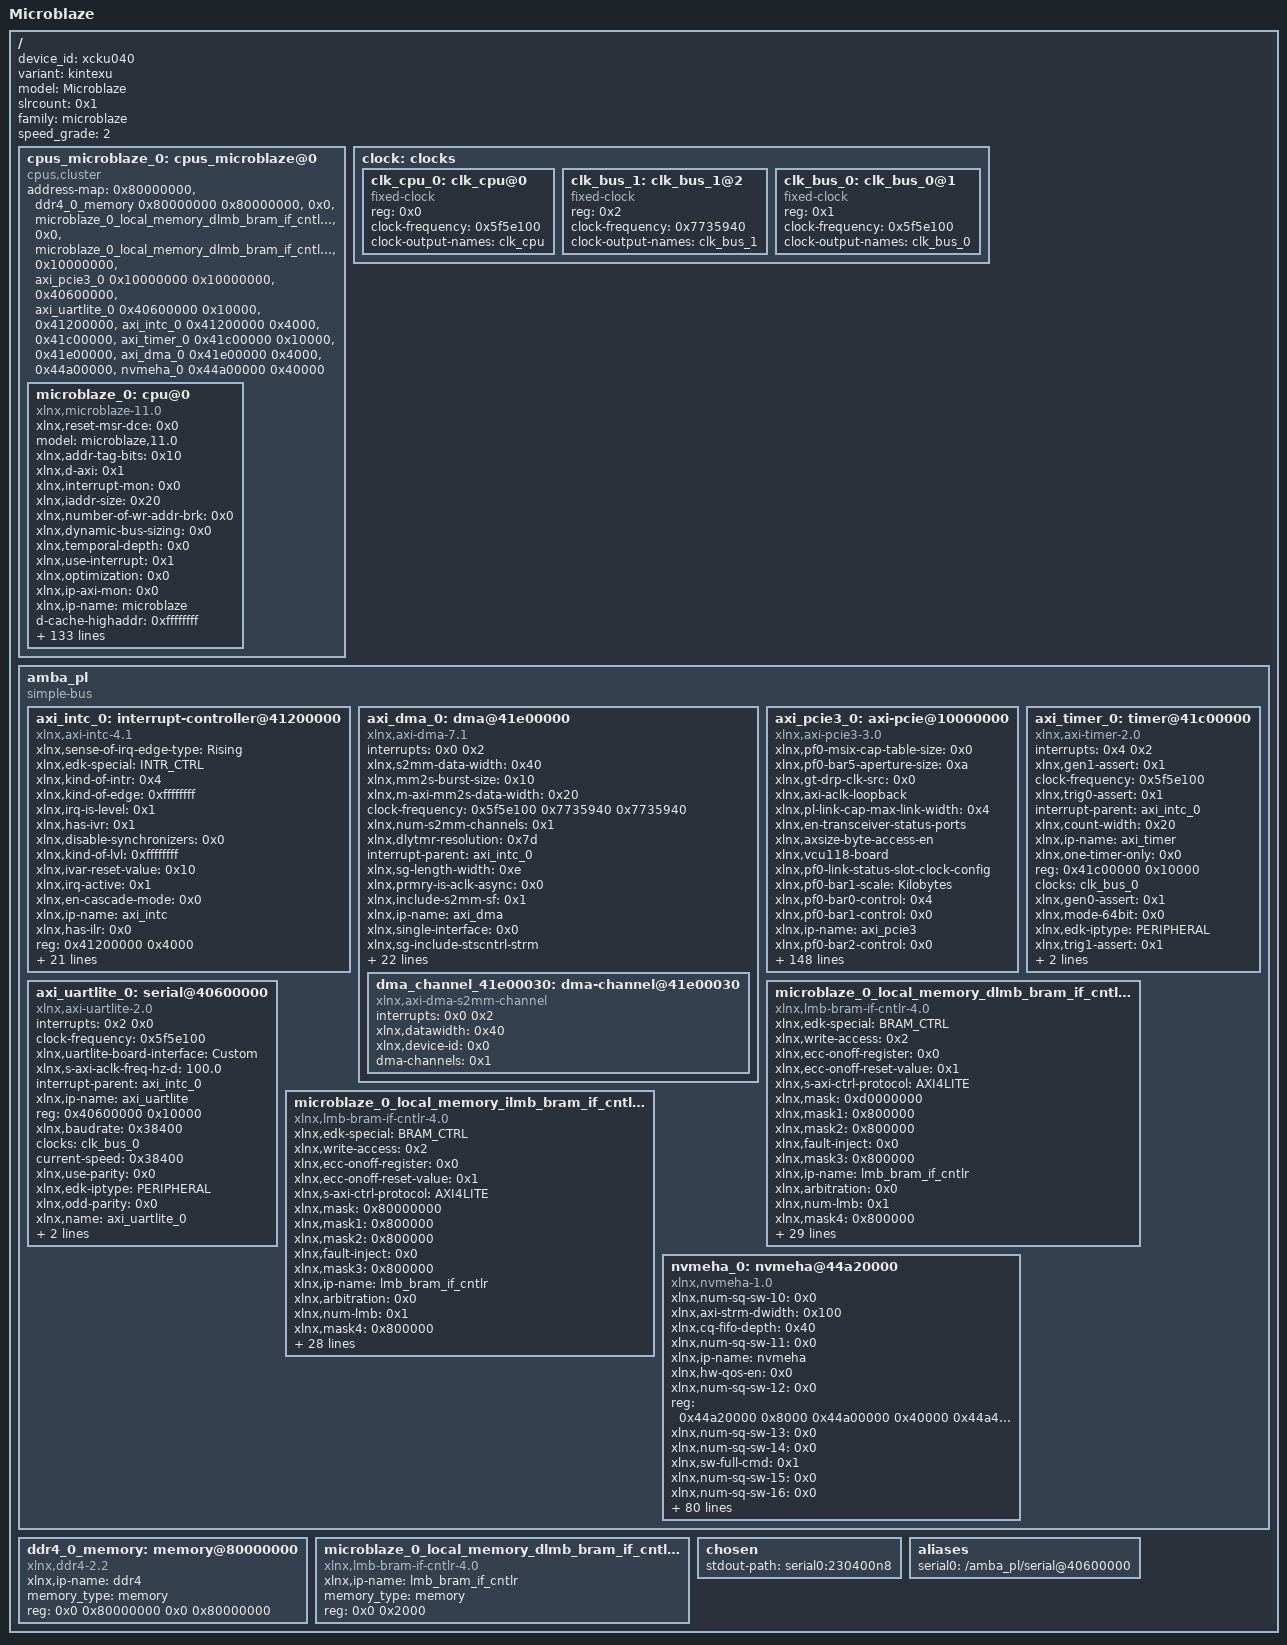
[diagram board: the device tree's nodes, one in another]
/dts-v1/;
/ {
        device_id = "xcku040";
        #address-cells = <0x1>;
        variant = "kintexu";
        model = "Microblaze";
        #size-cells = <0x1>;
        slrcount = <0x1>;
        family = "microblaze";
        speed_grade = "2";

        cpus_microblaze_0: cpus_microblaze@0 {
                phandle = <0xd>;
                #cpu-mask-cells = <0x1>;
                compatible = "cpus,cluster";
                #address-cells = <0x1>;
                #size-cells = <0x0>;
                address-map = <0x80000000 &ddr4_0_memory 0x80000000 0x80000000>,
                 <0x0 &microblaze_0_local_memory_dlmb_bram_if_cntlr_memory 0x0 0x2000>,
                 <0x0 &microblaze_0_local_memory_dlmb_bram_if_cntlr 0x0 0x2000>,
                 <0x10000000 &axi_pcie3_0 0x10000000 0x10000000>,
                 <0x40600000 &axi_uartlite_0 0x40600000 0x10000>,
                 <0x41200000 &axi_intc_0 0x41200000 0x4000>,
                 <0x41c00000 &axi_timer_0 0x41c00000 0x10000>,
                 <0x41e00000 &axi_dma_0 0x41e00000 0x4000>,
                 <0x44a00000 &nvmeha_0 0x44a00000 0x40000>;
                #ranges-address-cells = <0x1>;
                #ranges-size-cells = <0x1>;

                microblaze_0: cpu@0 {
                        phandle = <0xe>;
                        xlnx,reset-msr-dce = <0x0>;
                        model = "microblaze,11.0";
                        xlnx,addr-tag-bits = <0x10>;
                        xlnx,d-axi = <0x1>;
                        xlnx,interrupt-mon = <0x0>;
                        xlnx,iaddr-size = <0x20>;
                        xlnx,number-of-wr-addr-brk = <0x0>;
                        xlnx,dynamic-bus-sizing = <0x0>;
                        xlnx,temporal-depth = <0x0>;
                        xlnx,use-interrupt = <0x1>;
                        xlnx,optimization = <0x0>;
                        xlnx,ip-axi-mon = <0x0>;
                        xlnx,ip-name = "microblaze";
                        d-cache-highaddr = <0xffffffff>;
                        xlnx,dcache-force-tag-lutram = <0x0>;
                        xlnx,pc-width = <0x20>;
                        xlnx,interrupt-is-edge = <0x0>;
                        reg = <0x0>;
                        xlnx,async-interrupt = <0x1>;
                        xlnx,use-mmu = <0x3>;
                        xlnx,reset-msr-ee = <0x0>;
                        xlnx,icache-victims = <0x8>;
                        xlnx,use-reorder-instr = <0x1>;
                        xlnx,d-lmb-mon = <0x0>;
                        xlnx,d-lmb-protocol = <0x0>;
                        xlnx,ill-opcode-exception = <0x1>;
                        xlnx,dcache-always-used = <0x0>;
                        xlnx,use-div = <0x1>;
                        xlnx,dc-axi-mon = <0x0>;
                        xlnx,debug-trace-async-reset = <0x0>;
                        xlnx,trace = <0x0>;
                        xlnx,part = "xcku040-ffva1156-2-i";
                        i-cache-baseaddr = <0x80000000>;
                        xlnx,use-config-reset = <0x0>;
                        xlnx,pvr = <0x2>;
                        xlnx,i-lmb-mon = <0x0>;
                        xlnx,dcache-byte-size = <0x8000>;
                        xlnx,fault-tolerant = <0x0>;
                        xlnx,family = "kintexu";
                        compatible = "xlnx,microblaze-11.0", "xlnx,microblaze";
                        xlnx,data-size = <0x20>;
                        xlnx,mmu-zones = <0x2>;
                        xlnx,debug-trace-size = <0x2000>;
                        xlnx,mmu-privileged-instr = <0x0>;
                        xlnx,enable-discrete-ports = <0x0>;
                        d-cache-line-size = <0x10>;
                        xlnx,d-lmb = <0x1>;
                        xlnx,sco = <0x0>;
                        xlnx,reset-msr-eip = <0x0>;
                        xlnx,debug-interface = <0x0>;
                        clock-frequency = <0x5f5e100>;
                        xlnx,use-ext-brk = <0x0>;
                        xlnx,daddr-size = <0x20>;
                        xlnx,debug-enabled = <0x1>;
                        xlnx,reset-msr-ice = <0x0>;
                        xlnx,num-sync-ff-dbg-trace-clk = <0x2>;
                        xlnx,i-lmb-protocol = <0x0>;
                        xlnx,endianness = <0x1>;
                        xlnx,fsl-exception = <0x0>;
                        i-cache-line-size = <0x20>;
                        xlnx,use-extended-fsl-instr = <0x0>;
                        xlnx,reset-msr = <0x0>;
                        xlnx,dp-axi-mon = <0x0>;
                        device_type = "cpu";
                        xlnx,branch-target-cache-size = <0x0>;
                        xlnx,dcache-use-writeback = <0x0>;
                        xlnx,div-zero-exception = <0x1>;
                        xlnx,mmu-tlb-access = <0x3>;
                        bus-handle = <&amba_pl>;
                        xlnx,cache-byte-size = <0x8000>;
                        xlnx,pvr-user2 = <0x0>;
                        xlnx,opcode-0x0-illegal = <0x1>;
                        xlnx,icache-line-len = <0x8>;
                        xlnx,ecc-use-ce-exception = <0x0>;
                        xlnx,base-vectors = <0x0>;
                        xlnx,d-lmb-has-prot = <0x0>;
                        xlnx,edk-special = "microblaze";
                        xlnx,use-dcache = <0x1>;
                        xlnx,use-barrel = <0x1>;
                        xlnx,reset-msr-bip = <0x0>;
                        xlnx,allow-dcache-wr = <0x1>;
                        xlnx,debug-external-trace = <0x0>;
                        xlnx,addr-size = <0x20>;
                        xlnx,piaddr-size = <0x20>;
                        i-cache-highaddr = <0xffffffff>;
                        xlnx,num-sync-ff-clk-debug = <0x2>;
                        xlnx,debug-event-counters = <0x5>;
                        xlnx,fpu-exception = <0x0>;
                        xlnx,allow-icache-wr = <0x1>;
                        xlnx,g-use-exceptions = <0x1>;
                        xlnx,i-axi = <0x0>;
                        xlnx,g-template-list = <0x4>;
                        xlnx,icache-streams = <0x1>;
                        xlnx,dcache-line-len = <0x4>;
                        xlnx,num-sync-ff-clk = <0x2>;
                        xlnx,edk-iptype = "PROCESSOR";
                        xlnx,use-stack-protection = <0x0>;
                        xlnx,use-hw-mul = <0x2>;
                        xlnx,num-sync-ff-dbg-clk = <0x1>;
                        xlnx,interconnect = <0x2>;
                        xlnx,i-lmb-has-prot = <0x0>;
                        xlnx,debug-latency-counters = <0x1>;
                        i-cache-size = <0x8000>;
                        xlnx,exceptions-in-delay-slots = <0x1>;
                        xlnx,use-fpu = <0x0>;
                        xlnx,reset-msr-ie = <0x0>;
                        xlnx,edge-is-positive = <0x1>;
                        xlnx,use-pcmp-instr = <0x1>;
                        xlnx,use-icache = <0x1>;
                        d-cache-size = <0x8000>;
                        xlnx,memory-ip-list = "microblaze_0_local_memory_ilmb_bram_if_cntlr_memory", "microblaze_0_local_memory_dlmb_bram_if_cntlr_memory", "ddr4_0_memory", "ddr4_0_memory";
                        xlnx,async-wakeup = <0x3>;
                        xlnx,use-non-secure = <0x0>;
                        xlnx,dcache-addr-tag = <0x10>;
                        xlnx,number-of-rd-addr-brk = <0x0>;
                        d-cache-baseaddr = <0x80000000>;
                        xlnx,area-optimized = <0x0>;
                        xlnx,avoid-primitives = <0x0>;
                        xlnx,lockstep-slave = <0x0>;
                        xlnx,use-ext-nm-brk = <0x0>;
                        xlnx,instr-size = <0x20>;
                        interrupt-handle = <&axi_intc_0>;
                        xlnx,icache-always-used = <0x1>;
                        xlnx,i-lmb = <0x1>;
                        xlnx,mmu-dtlb-size = <0x4>;
                        xlnx,lockstep-select = <0x0>;
                        xlnx,lmb-data-size = <0x20>;
                        xlnx,ic-axi-mon = <0x0>;
                        xlnx,enable-conversion = <0x0>;
                        xlnx,num-sync-ff-clk-irq = <0x1>;
                        xlnx,fsl-links = <0x0>;
                        timebase-frequency = <0x5f5e100>;
                        xlnx,icache-force-tag-lutram = <0x0>;
                        xlnx,dcache-data-width = <0x0>;
                        xlnx,dcache-victims = <0x8>;
                        xlnx,use-branch-target-cache = <0x0>;
                        xlnx,debug-profile-size = <0x0>;
                        xlnx,unaligned-exceptions = <0x1>;
                        xlnx,lockstep-master = <0x0>;
                        xlnx,freq = <0x5f5e100>;
                        xlnx,number-of-pc-brk = <0x1>;
                        xlnx,mmu-itlb-size = <0x2>;
                        xlnx,imprecise-exceptions = <0x0>;
                        xlnx,use-msr-instr = <0x1>;
                        xlnx,icache-data-width = <0x0>;
                        xlnx,debug-counter-width = <0x20>;
                };
        };

        clock: clocks {
                phandle = <0xf>;
                #address-cells = <0x1>;
                #size-cells = <0x0>;

                clk_cpu_0: clk_cpu@0 {
                        phandle = <0x10>;
                        compatible = "fixed-clock";
                        reg = <0x0>;
                        clock-frequency = <0x5f5e100>;
                        clock-output-names = "clk_cpu";
                        #clock-cells = <0x0>;
                };

                clk_bus_1: clk_bus_1@2 {
                        phandle = <0xc>;
                        compatible = "fixed-clock";
                        reg = <0x2>;
                        clock-frequency = <0x7735940>;
                        clock-output-names = "clk_bus_1";
                        #clock-cells = <0x0>;
                };

                clk_bus_0: clk_bus_0@1 {
                        phandle = <0xb>;
                        compatible = "fixed-clock";
                        reg = <0x1>;
                        clock-frequency = <0x5f5e100>;
                        clock-output-names = "clk_bus_0";
                        #clock-cells = <0x0>;
                };
        };

        amba_pl: amba_pl {
                phandle = <0xa>;
                ranges;
                compatible = "simple-bus";
                #address-cells = <0x1>;
                #size-cells = <0x1>;

                axi_intc_0: interrupt-controller@41200000 {
                        phandle = <0x6>;
                        #interrupt-cells = <0x2>;
                        xlnx,sense-of-irq-edge-type = "Rising";
                        xlnx,edk-special = "INTR_CTRL";
                        xlnx,kind-of-intr = <0x4>;
                        xlnx,kind-of-edge = <0xffffffff>;
                        xlnx,irq-is-level = <0x1>;
                        xlnx,has-ivr = <0x1>;
                        compatible = "xlnx,axi-intc-4.1", "xlnx,xps-intc-1.00.a";
                        xlnx,disable-synchronizers = <0x0>;
                        xlnx,kind-of-lvl = <0xffffffff>;
                        xlnx,ivar-reset-value = <0x10>;
                        xlnx,irq-active = <0x1>;
                        xlnx,en-cascade-mode = <0x0>;
                        xlnx,ip-name = "axi_intc";
                        xlnx,has-ilr = <0x0>;
                        reg = <0x41200000 0x4000>;
                        xlnx,addr-width = <0x20>;
                        xlnx,s-axi-aclk-freq-mhz = "100.0";
                        xlnx,num-sw-intr = <0x0>;
                        xlnx,irq-connection = <0x0>;
                        xlnx,num-intr-inputs = <0x5>;
                        xlnx,has-sie = <0x1>;
                        xlnx,enable-async = <0x0>;
                        xlnx,has-cie = <0x1>;
                        xlnx,num-sync-ff = <0x2>;
                        xlnx,edk-iptype = "PERIPHERAL";
                        xlnx,mb-clk-not-connected = <0x1>;
                        xlnx,has-ipr = <0x1>;
                        xlnx,sense-of-irq-level-type = "Active_High";
                        xlnx,cascade-master = <0x0>;
                        xlnx,processor-clk-freq-mhz = "100.0";
                        status = "okay";
                        xlnx,is-fast = <0x0>;
                        xlnx,has-fast = <0x0>;
                        xlnx,ivar-rst-val = <0x10>;
                        interrupt-controller;
                        xlnx,async-intr = <0xffffffeb>;
                        xlnx,name = "axi_intc_0";
                };

                axi_dma_0: dma@41e00000 {
                        phandle = <0x8>;
                        interrupts = <0x0 0x2>;
                        compatible = "xlnx,axi-dma-7.1", "xlnx,axi-dma-1.00.a";
                        xlnx,s2mm-data-width = <0x40>;
                        xlnx,mm2s-burst-size = <0x10>;
                        xlnx,m-axi-mm2s-data-width = <0x20>;
                        clock-frequency = <0x5f5e100 0x7735940 0x7735940>;
                        xlnx,num-s2mm-channels = <0x1>;
                        xlnx,dlytmr-resolution = <0x7d>;
                        interrupt-parent = <&axi_intc_0>;
                        xlnx,sg-length-width = <0xe>;
                        xlnx,prmry-is-aclk-async = <0x0>;
                        xlnx,include-s2mm-sf = <0x1>;
                        #dma-cells = <0x1>;
                        xlnx,ip-name = "axi_dma";
                        xlnx,single-interface = <0x0>;
                        xlnx,sg-include-stscntrl-strm;
                        xlnx,include-s2mm-dre = <0x0>;
                        reg = <0x41e00000 0x4000>;
                        xlnx,addr-width = <0x20>;
                        xlnx,include-s2mm = <0x1>;
                        clocks = <&clk_bus_0>,
                         <&clk_bus_1>,
                         <&clk_bus_1>;
                        xlnx,s-axis-s2mm-tdata-width = <0x40>;
                        xlnx,micro-dma = <0x0>;
                        xlnx,increase-throughput = <0x0>;
                        xlnx,mm2s-data-width = <0x20>;
                        xlnx,addrwidth = <0x20>;
                        xlnx,include-sg;
                        xlnx,sg-use-stsapp-length = <0x0>;
                        xlnx,m-axis-mm2s-tdata-width = <0x20>;
                        xlnx,edk-iptype = "PERIPHERAL";
                        xlnx,s2mm-burst-size = <0x100>;
                        xlnx,m-axi-s2mm-data-width = <0x40>;
                        xlnx,num-mm2s-channels = <0x1>;
                        xlnx,enable-multi-channel = <0x0>;
                        status = "okay";
                        xlnx,include-mm2s-sf = <0x1>;
                        clock-names = "s_axi_lite_aclk", "m_axi_sg_aclk", "m_axi_s2mm_aclk";
                        interrupt-names = "s2mm_introut";
                        xlnx,include-mm2s = <0x0>;
                        xlnx,include-mm2s-dre = <0x0>;
                        xlnx,name = "axi_dma_0";

                        dma_channel_41e00030: dma-channel@41e00030 {
                                phandle = <0x11>;
                                interrupts = <0x0 0x2>;
                                xlnx,datawidth = <0x40>;
                                xlnx,device-id = <0x0>;
                                compatible = "xlnx,axi-dma-s2mm-channel";
                                dma-channels = <0x1>;
                        };
                };

                axi_pcie3_0: axi-pcie@10000000 {
                        phandle = <0x4>;
                        xlnx,pf0-msix-cap-table-size = <0x0>;
                        xlnx,pf0-bar5-aperture-size = <0xa>;
                        xlnx,gt-drp-clk-src = <0x0>;
                        xlnx,axi-aclk-loopback;
                        xlnx,pl-link-cap-max-link-width = <0x4>;
                        xlnx,en-transceiver-status-ports;
                        xlnx,axsize-byte-access-en;
                        xlnx,vcu118-board;
                        xlnx,pf0-link-status-slot-clock-config;
                        xlnx,pf0-bar1-scale = "Kilobytes";
                        xlnx,pf0-bar0-control = <0x4>;
                        xlnx,pf0-bar1-control = <0x0>;
                        xlnx,ip-name = "axi_pcie3";
                        xlnx,pf0-bar2-control = <0x0>;
                        xlnx,pf0-bar0-enabled;
                        reg = <0x10000000 0x10000000 0x76000000 0x100000 0x76100000 0x100000 0x10000000 0x4000>;
                        xlnx,user-clk-freq = <0x2>;
                        xlnx,pf0-class-code = <0x60700>;
                        xlnx,pf0-bar3-control = <0x0>;
                        xlnx,msix-en;
                        xlnx,pf0-bar5-scale = "Kilobytes";
                        xlnx,pf0-bar4-control = <0x0>;
                        xlnx,pf0-bar3-type = "Memory";
                        xlnx,enable-ibert;
                        xlnx,silicon-rev = "Production";
                        xlnx,pf0-bar5-control = <0x0>;
                        xlnx,pf0-revision-id = <0x0>;
                        xlnx,pf0-interrupt-pin = <0x1>;
                        xlnx,axibar-0 = <0x76000000>;
                        xlnx,pf0-device-id = <0x8134>;
                        xlnx,pf0-bar5-size = <0x4>;
                        xlnx,pf0-bar0-aperture-size = <0xa>;
                        xlnx,gt-tx-pd;
                        xlnx,pr-cap-nextptr = <0x0>;
                        xlnx,axibar-1 = <0x30000000>;
                        xlnx,en-axi-slave-if;
                        xlnx,axi-data-width = <0x100>;
                        xlnx,axibar-2 = <0x0>;
                        xlnx,type1-prefetchable-membase-memlimit = "Disabled";
                        xlnx,pf0-class-code-interface = <0x0>;
                        xlnx,pf0-bar0-type = "Memory";
                        xlnx,mcap-fpga-bitstream-version = <0x0>;
                        xlnx,axibar-3 = <0x0>;
                        interrupt-names = "interrupt_out";
                        xlnx,select-quad = "GTH_Quad_227";
                        xlnx,axibar-4 = <0x0>;
                        xlnx,include-baroffset-reg = <0x1>;
                        xlnx,pf0-bar4-aperture-size = <0xa>;
                        xlnx,s-axi-id-width = <0x4>;
                        xlnx,axibar-5 = <0x0>;
                        xlnx,pf0-bar2-size = <0x4>;
                        xlnx,enable-auto-rxeq;
                        compatible = "xlnx,axi-pcie3-3.0";
                        xlnx,cfg-ext-if;
                        xlnx,sys-rst-n-board-interface = "Custom";
                        xlnx,pciebar-num = <0x1>;
                        xlnx,ats-cap-nextptr = <0x0>;
                        xlnx,pf0-subsystem-id = <0x7>;
                        xlnx,axibar-num = <0x2>;
                        xlnx,pf0-bar0-scale = "Kilobytes";
                        xlnx,pciebar2axibar-1-sec = <0x0>;
                        interrupt-parent = <&axi_intc_0>;
                        xlnx,phy-lp-txpreset = <0x4>;
                        xlnx,coreclk-freq = <0xfa>;
                        xlnx,en-axi-master-if;
                        xlnx,pciebar2axibar-3-sec = <0x0>;
                        xlnx,rx-ppm-offset = <0x0>;
                        xlnx,pf0-sub-class-interface-menu = "CardBus_bridge";
                        xlnx,mode-selection = "Advanced";
                        xlnx,vu9p-board;
                        xlnx,ultrascale-plus;
                        xlnx,pf0-bar4-scale = "Kilobytes";
                        xlnx,pciebar2axibar-5-sec = <0x0>;
                        xlnx,m-axi-num-write = <0x8>;
                        xlnx,pf0-vendor-id = <0x10ee>;
                        xlnx,last-core-cap-addr = <0x100>;
                        xlnx,pipe-sim;
                        xlnx,pf0-msix-impl-locn = "External";
                        xlnx,pf0-msix-cap-table-bir = "BAR_0";
                        xlnx,pf0-bar5-type = "Memory";
                        xlnx,axibar-highaddr-0 = <0x760fffff>;
                        xlnx,axibar-highaddr-1 = <0x3fffffff>;
                        status = "okay";
                        xlnx,axibar-highaddr-2 = <0x0>;
                        xlnx,pll-type = <0x2>;
                        xlnx,pf0-subsystem-vendor-id = <0x10ee>;
                        xlnx,pf0-msix-cap-pba-bir = "BAR_0";
                        xlnx,axibar-highaddr-3 = <0x0>;
                        xlnx,pf0-msi-cap-multimsgcap = <0x0>;
                        xlnx,pf0-bar3-aperture-size = <0xa>;
                        xlnx,dev-port-type = <0x2>;
                        xlnx,timeout0-sel = <0xe>;
                        xlnx,axibar-highaddr-4 = <0x0>;
                        xlnx,pf0-class-code-base = <0x6>;
                        xlnx,pf0-bar2-type = "Memory";
                        xlnx,msi-enabled;
                        xlnx,name = "axi_pcie3_0";
                        xlnx,axibar-highaddr-5 = <0x0>;
                        interrupts = <0x3 0x2>;
                        xlnx,plltype = "QPLL1";
                        xlnx,vsec-cap-addr = <0x128>;
                        xlnx,pf0-base-class-menu = "Bridge_device";
                        xlnx,pf0-bar4-size = <0x4>;
                        xlnx,is-board-project = <0x0>;
                        xlnx,timeout-mult = <0x3>;
                        xlnx,axi-addr-width = <0x20>;
                        xlnx,axisten-freq = <0x7d>;
                        xlnx,pf0-bar3-scale = "Kilobytes";
                        xlnx,s-axi-num-read = <0x8>;
                        xlnx,pf0-bar1-size = <0x4>;
                        xlnx,comp-timeout = <0x0>;
                        xlnx,edk-iptype = "PERIPHERAL";
                        xlnx,ins-loss-nyq = <0xf>;
                        xlnx,msix-impl-ext;
                        xlnx,ins-loss-profile = "Add-in_Card";
                        xlnx,pf0-bar2-aperture-size = <0xa>;
                        xlnx,vendor-id = "10EE";
                        xlnx,ultrascale;
                        xlnx,sys-reset-polarity = <0x0>;
                        xlnx,rx-detect = <0x0>;
                        xlnx,pf0-class-code-sub = <0x7>;
                        xlnx,m-axi-num-read = <0x8>;
                        xlnx,pf0-bar4-type = "Memory";
                        xlnx,pl-link-cap-max-link-speed = <0x4>;
                        xlnx,enable-jtag-dbg;
                        xlnx,pciebar2axibar-0-sec = <0x0>;
                        xlnx,pf0-msix-cap-table-offset = <0x0>;
                        xlnx,pciebar2axibar-2-sec = <0x0>;
                        xlnx,pf0-bar2-scale = "Kilobytes";
                        xlnx,pf0-bar1-type = "Memory";
                        xlnx,pcie-blk-locn = <0x1>;
                        xlnx,pciebar2axibar-4-sec = <0x0>;
                        xlnx,shared-logic = <0x1>;
                        xlnx,rx-ssc-ppm = <0x0>;
                        xlnx,pf0-bar3-size = <0x4>;
                        xlnx,core-clk-freq = <0x1>;
                        xlnx,pf0-msi-enabled;
                        xlnx,pcie-board-interface = "Custom";
                        xlnx,axibar2pciebar-0 = <0x0>;
                        xlnx,pciebar2axibar-0 = <0x0>;
                        xlnx,no-slv-err;
                        xlnx,axibar2pciebar-1 = <0x0>;
                        xlnx,old-bridge-timeout = <0x0>;
                        xlnx,pciebar2axibar-1 = <0x0>;
                        xlnx,pf0-bar1-aperture-size = <0xa>;
                        xlnx,axibar2pciebar-2 = <0x0>;
                        xlnx,pciebar2axibar-2 = <0x0>;
                        xlnx,ref-clk-freq = <0x0>;
                        xlnx,s-axi-num-write = <0x8>;
                        xlnx,axibar2pciebar-3 = <0x0>;
                        xlnx,pciebar2axibar-3 = <0x0>;
                        xlnx,pf0-bar0-size = <0x4>;
                        xlnx,axibar2pciebar-4 = <0x0>;
                        xlnx,pciebar2axibar-4 = <0x0>;
                        xlnx,xlnx-ref-board = "None";
                        xlnx,type1-membase-memlimit-enable = "Disabled";
                        xlnx,pf0-msix-cap-pba-offset = <0x0>;
                        xlnx,mcap-enablement = "NONE";
                        xlnx,timeout1-sel = <0xf>;
                        xlnx,pciebar2axibar-5 = <0x0>;
                        xlnx,axibar2pciebar-5 = <0x0>;
                        xlnx,component-name = "axi_pcie3_v3_0";
                };

                axi_timer_0: timer@41c00000 {
                        phandle = <0x7>;
                        interrupts = <0x4 0x2>;
                        compatible = "xlnx,axi-timer-2.0", "xlnx,xps-timer-1.00.a";
                        xlnx,gen1-assert = <0x1>;
                        clock-frequency = <0x5f5e100>;
                        xlnx,trig0-assert = <0x1>;
                        interrupt-parent = <&axi_intc_0>;
                        xlnx,count-width = <0x20>;
                        xlnx,ip-name = "axi_timer";
                        xlnx,one-timer-only = <0x0>;
                        reg = <0x41c00000 0x10000>;
                        clocks = <&clk_bus_0>;
                        xlnx,gen0-assert = <0x1>;
                        xlnx,mode-64bit = <0x0>;
                        xlnx,edk-iptype = "PERIPHERAL";
                        status = "okay";
                        xlnx,trig1-assert = <0x1>;
                        xlnx,enable-timer2 = <0x1>;
                        interrupt-names = "interrupt";
                        xlnx,name = "axi_timer_0";
                };

                axi_uartlite_0: serial@40600000 {
                        phandle = <0x5>;
                        interrupts = <0x2 0x0>;
                        compatible = "xlnx,axi-uartlite-2.0", "xlnx,xps-uartlite-1.00.a";
                        clock-frequency = <0x5f5e100>;
                        xlnx,uartlite-board-interface = "Custom";
                        xlnx,s-axi-aclk-freq-hz-d = "100.0";
                        interrupt-parent = <&axi_intc_0>;
                        xlnx,ip-name = "axi_uartlite";
                        reg = <0x40600000 0x10000>;
                        xlnx,baudrate = <0x38400>;
                        clocks = <&clk_bus_0>;
                        current-speed = <0x38400>;
                        xlnx,use-parity = <0x0>;
                        xlnx,edk-iptype = "PERIPHERAL";
                        xlnx,odd-parity = <0x0>;
                        status = "okay";
                        interrupt-names = "interrupt";
                        xlnx,name = "axi_uartlite_0";
                        xlnx,data-bits = <0x8>;
                        xlnx,parity = "No_Parity";
                };

                microblaze_0_local_memory_dlmb_bram_if_cntlr: lmb_bram_if_cntlr@0 {
                        phandle = <0x3>;
                        xlnx,edk-special = "BRAM_CTRL";
                        xlnx,write-access = <0x2>;
                        compatible = "xlnx,lmb-bram-if-cntlr-4.0", "xlnx,axi-bram-ctrl";
                        xlnx,ecc-onoff-register = <0x0>;
                        xlnx,ecc-onoff-reset-value = <0x1>;
                        xlnx,s-axi-ctrl-protocol = "AXI4LITE";
                        xlnx,mask = <0xd0000000>;
                        xlnx,mask1 = <0x800000>;
                        xlnx,mask2 = <0x800000>;
                        xlnx,fault-inject = <0x0>;
                        xlnx,mask3 = <0x800000>;
                        xlnx,ip-name = "lmb_bram_if_cntlr";
                        xlnx,arbitration = <0x0>;
                        xlnx,num-lmb = <0x1>;
                        xlnx,mask4 = <0x800000>;
                        reg = <0x0 0x2000>;
                        xlnx,s-axi-ctrl-addr-width = <0x20>;
                        xlnx,mask5 = <0x800000>;
                        xlnx,ecc-status-registers = <0x0>;
                        xlnx,prot-cfg = <0xff>;
                        xlnx,mask6 = <0x800000>;
                        xlnx,lmb-protocol = <0x0>;
                        xlnx,ce-counter-width = <0x0>;
                        xlnx,prot-cfg1 = <0xff>;
                        xlnx,mask7 = <0x800000>;
                        xlnx,ecc = <0x0>;
                        xlnx,edk-iptype = "PERIPHERAL";
                        xlnx,prot-cfg2 = <0xff>;
                        xlnx,lmb-dwidth = <0x20>;
                        xlnx,interconnect = <0x0>;
                        xlnx,ce-failing-registers = <0x0>;
                        xlnx,prot-cfg3 = <0xff>;
                        xlnx,ue-failing-registers = <0x0>;
                        xlnx,prot-cfg4 = <0xff>;
                        xlnx,lmb-has-prot = <0x0>;
                        status = "okay";
                        xlnx,data-width = <0x20>;
                        xlnx,prot-cfg5 = <0xff>;
                        xlnx,s-axi-ctrl-data-width = <0x20>;
                        xlnx,prot-cfg6 = <0xff>;
                        xlnx,bram-awidth = <0x20>;
                        xlnx,prot-cfg7 = <0xff>;
                        xlnx,lmb-awidth = <0x20>;
                        xlnx,name = "microblaze_0_local_memory_dlmb_bram_if_cntlr";
                };

                microblaze_0_local_memory_ilmb_bram_if_cntlr: microblaze_0_local_memory_ilmb_bram_if_cntlr@0 {
                        phandle = <0x12>;
                        xlnx,edk-special = "BRAM_CTRL";
                        xlnx,write-access = <0x2>;
                        compatible = "xlnx,lmb-bram-if-cntlr-4.0", "xlnx,axi-bram-ctrl";
                        xlnx,ecc-onoff-register = <0x0>;
                        xlnx,ecc-onoff-reset-value = <0x1>;
                        xlnx,s-axi-ctrl-protocol = "AXI4LITE";
                        xlnx,mask = <0x80000000>;
                        xlnx,mask1 = <0x800000>;
                        xlnx,mask2 = <0x800000>;
                        xlnx,fault-inject = <0x0>;
                        xlnx,mask3 = <0x800000>;
                        xlnx,ip-name = "lmb_bram_if_cntlr";
                        xlnx,arbitration = <0x0>;
                        xlnx,num-lmb = <0x1>;
                        xlnx,mask4 = <0x800000>;
                        reg = <0x0 0x2000>;
                        xlnx,s-axi-ctrl-addr-width = <0x20>;
                        xlnx,mask5 = <0x800000>;
                        xlnx,ecc-status-registers = <0x0>;
                        xlnx,prot-cfg = <0xff>;
                        xlnx,mask6 = <0x800000>;
                        xlnx,lmb-protocol = <0x0>;
                        xlnx,ce-counter-width = <0x0>;
                        xlnx,prot-cfg1 = <0xff>;
                        xlnx,mask7 = <0x800000>;
                        xlnx,ecc = <0x0>;
                        xlnx,edk-iptype = "PERIPHERAL";
                        xlnx,prot-cfg2 = <0xff>;
                        xlnx,lmb-dwidth = <0x20>;
                        xlnx,interconnect = <0x0>;
                        xlnx,ce-failing-registers = <0x0>;
                        xlnx,prot-cfg3 = <0xff>;
                        xlnx,ue-failing-registers = <0x0>;
                        xlnx,prot-cfg4 = <0xff>;
                        xlnx,lmb-has-prot = <0x0>;
                        status = "okay";
                        xlnx,prot-cfg5 = <0xff>;
                        xlnx,s-axi-ctrl-data-width = <0x20>;
                        xlnx,prot-cfg6 = <0xff>;
                        xlnx,bram-awidth = <0x20>;
                        xlnx,prot-cfg7 = <0xff>;
                        xlnx,lmb-awidth = <0x20>;
                        xlnx,name = "microblaze_0_local_memory_ilmb_bram_if_cntlr";
                };

                nvmeha_0: nvmeha@44a20000 {
                        phandle = <0x9>;
                        xlnx,num-sq-sw-10 = <0x0>;
                        xlnx,axi-strm-dwidth = <0x100>;
                        xlnx,cq-fifo-depth = <0x40>;
                        xlnx,num-sq-sw-11 = <0x0>;
                        xlnx,ip-name = "nvmeha";
                        xlnx,hw-qos-en = <0x0>;
                        xlnx,num-sq-sw-12 = <0x0>;
                        reg = <0x44a20000 0x8000 0x44a00000 0x40000 0x44a40000 0x10000 0x44a50000 0x10000>;
                        xlnx,num-sq-sw-13 = <0x0>;
                        xlnx,num-sq-sw-14 = <0x0>;
                        xlnx,sw-full-cmd = <0x1>;
                        xlnx,num-sq-sw-15 = <0x0>;
                        xlnx,num-sq-sw-16 = <0x0>;
                        xlnx,num-sq-sw-17 = <0x0>;
                        xlnx,num-sq-sw-18 = <0x0>;
                        xlnx,num-sq-sw-20 = <0x0>;
                        xlnx,num-sq-sw-19 = <0x0>;
                        interrupt-names = "ha_interrupt";
                        xlnx,num-sq-sw-21 = <0x0>;
                        xlnx,hw-full-cmd = <0x0>;
                        xlnx,s-axi-id-width = <0x4>;
                        xlnx,num-sq-sw-22 = <0x0>;
                        xlnx,sw-qos-en = <0x1>;
                        xlnx,sq-depth-hw = <0x20>;
                        xlnx,num-sq-sw-23 = <0x0>;
                        compatible = "xlnx,nvmeha-1.0";
                        xlnx,statistics-en = <0x1>;
                        xlnx,num-sq-sw-24 = <0x0>;
                        xlnx,en-hw-if = <0x0>;
                        xlnx,num-sq-sw-25 = <0x0>;
                        xlnx,num-sq-sw-26 = <0x0>;
                        interrupt-parent = <&axi_intc_0>;
                        xlnx,num-sq-sw-27 = <0x0>;
                        xlnx,num-ssd = <0x1>;
                        xlnx,num-sq-sw-28 = <0x0>;
                        xlnx,num-sq-sw-30 = <0x0>;
                        xlnx,num-sq-sw-29 = <0x0>;
                        xlnx,cq-new-db-logic = <0x0>;
                        xlnx,num-sq-sw-31 = <0x0>;
                        xlnx,num-sq-hw-10 = <0x0>;
                        xlnx,num-sq-hw-11 = <0x0>;
                        xlnx,num-sq-hw-12 = <0x0>;
                        status = "okay";
                        xlnx,num-sq-hw-13 = <0x0>;
                        xlnx,debug-en = <0x0>;
                        xlnx,num-sq-hw-14 = <0x0>;
                        xlnx,num-sq-hw-15 = <0x0>;
                        xlnx,name = "nvmeha_0";
                        xlnx,num-sq-hw-16 = <0x0>;
                        interrupts = <0x1 0x2>;
                        xlnx,num-sq-hw-0 = <0x0>;
                        xlnx,num-sq-hw-17 = <0x0>;
                        xlnx,uram-avlbl = <0x0>;
                        xlnx,num-sq-hw-1 = <0x0>;
                        xlnx,num-sq-hw-18 = <0x0>;
                        xlnx,num-sq-hw-19 = <0x0>;
                        xlnx,num-sq-hw-2 = <0x0>;
                        xlnx,num-sq-hw-20 = <0x0>;
                        xlnx,num-sq-hw-21 = <0x0>;
                        xlnx,num-sq-hw-3 = <0x0>;
                        xlnx,axi-lite-dwidth = <0x20>;
                        xlnx,num-sq-hw-22 = <0x0>;
                        xlnx,num-sq-hw-4 = <0x0>;
                        xlnx,num-sq-hw-23 = <0x0>;
                        xlnx,num-sq-hw-5 = <0x0>;
                        xlnx,num-sq-hw-24 = <0x0>;
                        xlnx,num-sq-hw-6 = <0x0>;
                        xlnx,sq-new-db-logic = <0x0>;
                        xlnx,num-sq = <0x4>;
                        xlnx,num-sq-hw-25 = <0x0>;
                        xlnx,num-sq-hw-7 = <0x0>;
                        xlnx,num-sq-hw-26 = <0x0>;
                        xlnx,num-sq-hw-8 = <0x0>;
                        xlnx,num-sq-hw-27 = <0x0>;
                        xlnx,num-sq-hw-9 = <0x0>;
                        xlnx,edk-iptype = "PERIPHERAL";
                        xlnx,num-sq-hw-28 = <0x0>;
                        xlnx,num-sq-hw-29 = <0x0>;
                        xlnx,num-sq-hw-30 = <0x0>;
                        xlnx,num-sq-hw-31 = <0x0>;
                        xlnx,axi-mem-dwidth = <0x40>;
                        xlnx,axi-ssd-dwidth = <0x80>;
                        xlnx,sq-depth-sw = <0x40>;
                        xlnx,num-sq-sw-0 = <0x4>;
                        xlnx,num-sq-sw-1 = <0x0>;
                        xlnx,num-sq-sw-2 = <0x0>;
                        xlnx,num-sq-sw-3 = <0x0>;
                        xlnx,num-sq-sw-4 = <0x0>;
                        xlnx,num-sq-sw-5 = <0x0>;
                        xlnx,num-sq-sw-6 = <0x0>;
                        xlnx,num-sq-sw-7 = <0x0>;
                        xlnx,num-sq-sw-8 = <0x0>;
                        xlnx,num-sq-sw-9 = <0x0>;
                        xlnx,en-sw-if = <0x1>;
                        xlnx,s-axi-ssd-id-width = <0x1>;
                        xlnx,axi-strm-mstr-dwidth = <0x80>;
                };
        };

        ddr4_0_memory: memory@80000000 {
                phandle = <0x1>;
                compatible = "xlnx,ddr4-2.2";
                xlnx,ip-name = "ddr4";
                device_type = "memory";
                memory_type = "memory";
                reg = <0x0 0x80000000 0x0 0x80000000>;
        };

        microblaze_0_local_memory_dlmb_bram_if_cntlr_memory: memory@0 {
                phandle = <0x2>;
                compatible = "xlnx,lmb-bram-if-cntlr-4.0", "mmio-sram";
                xlnx,ip-name = "lmb_bram_if_cntlr";
                device_type = "memory";
                memory_type = "memory";
                reg = <0x0 0x2000>;
        };

        chosen {
                stdout-path = "serial0:230400n8";
        };

        aliases {
                serial0 = "/amba_pl/serial@40600000";
        };

        __symbols__ {
                cpus_microblaze_0 = "/cpus_microblaze@0";
                microblaze_0 = "/cpus_microblaze@0/cpu@0";
                clock = "/clocks";
                clk_cpu_0 = "/clocks/clk_cpu@0";
                clk_bus_1 = "/clocks/clk_bus_1@2";
                clk_bus_0 = "/clocks/clk_bus_0@1";
                amba_pl = "/amba_pl";
                axi_intc_0 = "/amba_pl/interrupt-controller@41200000";
                axi_dma_0 = "/amba_pl/dma@41e00000";
                dma_channel_41e00030 = "/amba_pl/dma@41e00000/dma-channel@41e00030";
                axi_pcie3_0 = "/amba_pl/axi-pcie@10000000";
                axi_timer_0 = "/amba_pl/timer@41c00000";
                axi_uartlite_0 = "/amba_pl/serial@40600000";
                microblaze_0_local_memory_dlmb_bram_if_cntlr = "/amba_pl/lmb_bram_if_cntlr@0";
                microblaze_0_local_memory_ilmb_bram_if_cntlr = "/amba_pl/microblaze_0_local_memory_ilmb_bram_if_cntlr@0";
                nvmeha_0 = "/amba_pl/nvmeha@44a20000";
                ddr4_0_memory = "/memory@80000000";
                microblaze_0_local_memory_dlmb_bram_if_cntlr_memory = "/memory@0";
        };
};
